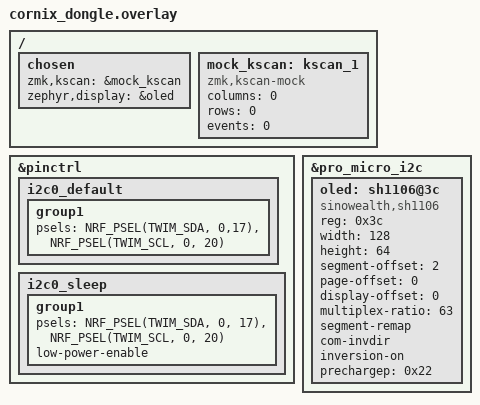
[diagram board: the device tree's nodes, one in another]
/*
 * Copyright (c) 2020 Pete Johanson
 *
 * SPDX-License-Identifier: MIT
 */

#include <dt-bindings/zmk/matrix_transform.h>
#include "cornix-layouts.dtsi"

#include "cornix_sensors.dtsi"
/{
    chosen {
        zmk,kscan = &mock_kscan;
        zephyr,display = &oled;
    };
    mock_kscan: kscan_1 {
        compatible = "zmk,kscan-mock";
        columns = <0>;
        rows = <0>;
        events = <0>;
    };
};

&pinctrl {
    i2c0_default: i2c0_default {
        group1 {
            psels = <NRF_PSEL(TWIM_SDA, 0,17)>,
                <NRF_PSEL(TWIM_SCL, 0, 20)>;
        };
    };

    i2c0_sleep: i2c0_sleep {
        group1 {
            psels = <NRF_PSEL(TWIM_SDA, 0, 17)>,
                <NRF_PSEL(TWIM_SCL, 0, 20)>;
            low-power-enable;
        };
    };	
}; 


&pro_micro_i2c {
    status = "okay";
    
    oled: sh1106@3c {
        compatible = "sinowealth,sh1106";
        reg = <0x3c>;
        width = <128>;
        height = <64>;
        segment-offset = <2>;
        page-offset = <0>;
        display-offset = <0>;
        multiplex-ratio = <63>;
        segment-remap;
        com-invdir;
        inversion-on;
        prechargep = <0x22>;
    };
};


// vim: set ft=dts :
